# nrf9120_MLM1 register map
Vendor: Nordic Semiconductor; Series: nrf91; File version: 1
CPU: CM4 r0p1, little endian, MPU, FPU, 3 interrupt priority bits
Registers are 32-bit, read-write, reset 0x0 unless marked. A register's access mark holds for its fields unless they carry their own. Offsets are from the block's base; [hi:lo] are bit positions; 'fields as' and 'values as' point back to an identical list.

## REGULATORS — Voltage Regulators control
Base 0x40003000
0x434 DISABLEHPBOR — Enable or disable HPBOR
  [0] DISABLE
    0=Enabled (Enable HPBOR); 1=Disabled (Disable HPBOR)
0x500 SYSTEMOFF wo
  [0] SYSTEMOFF — Enable System OFF mode
    1=Enable System OFF mode
0x508 UNUSED0 — Unspecified
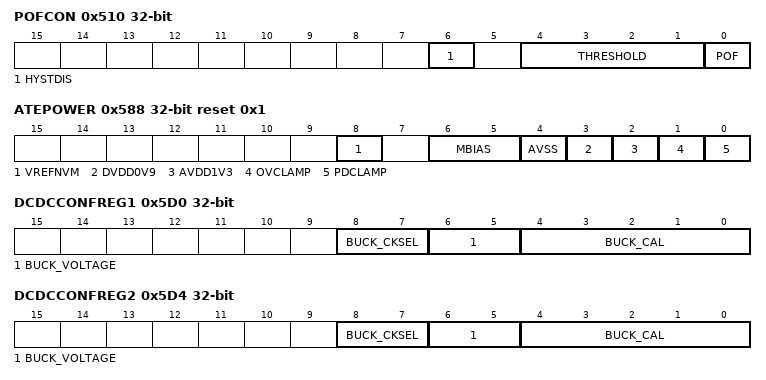
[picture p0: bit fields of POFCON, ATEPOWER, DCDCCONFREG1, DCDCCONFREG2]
0x510 POFCON — Power failure comparator configuration
  [6] HYSTDIS — Bypass power failure comparator hysteresis
    0=Normal (Hysteresis active); 1=NoHyst (Hysteresis disabled)
  [4:1] THRESHOLD — Power failure comparator threshold setting
    4=V17 (Set threshold to 1.7 V); 5=V18 (Set threshold to 1.8 V); 6=V19 (Set threshold to 1.9 V); 7=V20 (Set threshold to 2.0 V); 8=V21 (Set threshold to 2.1 V); 9=V22 (Set threshold to 2.2 V); 10=V23 (Set threshold to 2.3 V); 11=V24 (Set threshold to 2.4 V); 12=V25 (Set threshold to 2.5 V); 13=V26 (Set threshold to 2.6 V); 14=V27 (Set threshold to 2.7 V); 15=V28 (Set threshold to 2.8 V)
  [0] POF — Enable or disable power failure comparator
    0=Disabled; 1=Enabled
0x548 FORCEOFFNVM — Force off NVM supply. See also the internal section in the NVMC chapter.
  [31:0] FORCEOFFNVM
    on read: 0=DoNotForceOff (Read: Do not force off NVM supply.); 1=ForceOff (Read: Force off NVM supply.) | on write: 0=DisableForceOff (Write: Do not force off NVM supply.); 0xBADCA81E=EnableForceOff (Write: Force off NVM supply.)
0x578 DCDCEN — DC/DC enable register for REG1 (DVDD_0V9).
  [0] DCDCEN — Enable or disable DC/DC converter
    0=Disabled; 1=Enabled
0x57C DCDCEN2 — DC/DC enable register for REG2 (AVDD_1V3)
  [0] DCDCEN — Enable or disable DC/DC mode.
    0=Disabled; 1=Enabled
0x580 DCDCENMIR — Enable mirroring of DCDCEN register into DCDCEN2 register.
  [0] DCDCENMIR — Enable or disable mirroring of DCDCEN register into DCDCEN2 register.
    0=Disabled (DCDCEN and DCDCEN2 can be set independently); 1=Enabled (DCDCEN2 is a mirrored version of DCDCEN register.)
0x588 ATEPOWER reset 0x1 — Analog test bus control for power modules
  [8] VREFNVM — Connect or disconnect reference generator for flash to analog test bus
    0=Disconnected; 1=Connected (Connect 0.9 V downscaled reference voltage to ATB0)
  [6:5] MBIAS — Configure connection of master bias generator to analog test bus
    0=Disconnected; 1=VBG (Connect 0.9 V bandgap voltage to ATB0); 2=IBPSR10U (Connect 10 uA IBPSR current to ATB1); 3=Both (Connect both VBG to ATB0 and IBPSR10U to ATB1)
  [4] AVSS — Connect or disconnect AVSS to analog test bus
    0=Disconnected; 1=Connected (Connect to ATB1)
  [3] DVDD0V9 — Connect or disconnect DVDD_0V9 to analog test bus
    0=Disconnected; 1=Connected (Connect to ATB0)
  [2] AVDD1V3 — Connect or disconnect AVDD_1V3 to analog test bus
    0=Disconnected; 1=Connected (Connect to ATB0)
  [1] OVCLAMP — Enable or disable overvoltage clamp on analog test bus
    0=Disabled; 1=Enabled
  [0] PDCLAMP — Enable or disable power-down clamp on analog test bus
    0=Disabled; 1=Enabled
0x5D0 DCDCCONFREG1 — Configuration register for REG1 DCDC regulator (DVDD_0V9).
  [8:7] BUCK_CKSEL — Input clock selection.
    0=NORMAL (normal clock); 1=INVERTED (inverted clock)
  [6:5] BUCK_VOLTAGE — Output voltage selection.
    0=1V00 (1.00 V); 1=1V09 (1.09 V); 2=1V17 (1.17 V); 3=1V26 (1.26 V)
  [4:0] BUCK_CAL — Output voltage calibration. 0: Minimum output voltage level. 31: Maximum output voltage level.
0x5D4 DCDCCONFREG2 — Configuration register for REG2 DCDC regulator (AVDD_1V3).
  fields as DCDCCONFREG1
0xA08 UNUSED1 — Unspecified
0xA0C UNUSED2 — Unspecified
0xA10 FORCEMODEREG1 — A backdoor register for manual selection of REG1 regulator mode (DVDD_0V9)
  [6:0] FORCEMODE — Force Regulator Power Mode
    0=EXT (Force external (DVDD_0V9 supplied externally)); 1=ULP (Force ULP mode); 2=LDO (Force LDO mode); 3=DCDC (Force DCDC mode); 4=DCDC_REFRESH (Force DCDC REFRESH mode)
0xA20 THRESHOLDREG1 wo — Set threshold value of REG1 DCDC regulator
  [6:0] THRESHOLD — Sets the threshold value of power regulator. Note: The reset value comes from FICR (see FICR chapter for details)
0xA24 ENFORCEMODEREG1 wo — Enable forcing of power mode in REG1 voltage regulator
  [0] ENFORCEMODE — Enable forcing of power mode in voltage regulator
    0=Disabled (Regulator mode forcing OFF); 1=Enabled (Regulator forced ON in a power mode given by FORCEREGMODE1)
0xA28 IGNOREDAPCMODE wo — Ignore DAPCP power mode
  [0] IGNOREDAPCMODE — Ignore power request from debugger
    0=Do not ignore power request form debugger; 1=Ignore power request from debugger
0xA2C CURRENTMODEREG1 ro — Currently used power mode of the REG1 voltage regulator
  [6:0] CURRENTMODE — Currently used mode of the voltage regulator
    0=EXT (Externally supplied DVDD_0V9); 2=DCDC (DCDC mode); 3=DCDC_REFRESH (DCDC REFRESH mode); 4=LDO (LDO mode); 6=LDO_DCDC (swithching between LDO and DCDC (in any direction) Intermediate state when both regulators are ON); 7=LDO_DCDC_REFRESH (swithching between LDO and DCDC-REFRESH (in any direction) Intermediate state when both regulators are ON); 8=ULP (ULP mode); 10=DCDC_ULP (swithching from DCDC to ULP Intermediate state when both regulators are ON); 11=DCDC_REFRESH_ULP (swithching from DCDC-REFRESH to ULP Intermediate state when both regulators are ON); 12=ULP_LDO (swithching between ULP and LDO (in any direction) Intermediate state when both regulators are ON)
0xA30 FORCEMODEREG2 — A backdoor register for manual selection of REG2 regulator mode (DVDD_1V3)
  [6:0] FORCEMODE — Force Regulator Power Mode
    0=EXT (Force external (AVDD_1V3 supplied externally)); 1=ULP (Force ULP mode); 2=LDO (Force LDO mode); 3=DCDC (Force DCDC mode); 4=DCDC_REFRESH (Force DCDC REFRESH mode)
0xA38 THRESHOLDREG2 wo — Set threshold value of REG2 DCDC regulator
  fields as THRESHOLDREG1
0xA3C ENFORCEMODEREG2 wo — Enable forcing of power mode in REG2 voltage regulator
  [0] ENFORCEMODE — Enable forcing of power mode in voltage regulator
    0=Disabled (Regulator mode forcing OFF); 1=Enabled (Regulator forced ON in a power mode given by FORCEREGMODE2)
0xA40 DISABLEHSLIMITREG2 — Disable HSLIMIT for REG2 DCDC regulator
  [0] DISABLE — Enable or disable HSLIMIT for DCDC regulator
    0=Enabled (Enable HSLIMIT); 1=Disabled (Disable HSLIMIT)
0xA44 CURRENTMODEREG2 ro — Currently used power mode of the REG2 voltage regulator
  [6:0] CURRENTMODE — Currently used mode of the voltage regulator
    0=EXT (Externally supplied AVDD_1V3); 2=DCDC (DCDC mode); 3=DCDC_REFRESH (DCDC REFRESH mode); 4=LDO (LDO mode); 6=LDO_DCDC (swithching between LDO and DCDC (in any direction) Intermediate state when both regulators are ON); 7=LDO_DCDC_REFRESH (swithching between LDO and DCDC-REFRESH (in any direction) Intermediate state when both regulators are ON); 8=ULP (ULP mode); 10=DCDC_ULP (swithching from DCDC to ULP Intermediate state when both regulators are ON); 11=DCDC_REFRESH_ULP (swithching from DCDC-REFRESH to ULP Intermediate state when both regulators are ON); 12=ULP_LDO (swithching between ULP and LDO (in any direction) Intermediate state when both regulators are ON)
0xA48 DISABLEHSLIMITREG1 — Disable HSLIMIT for REG1 DCDC regulator
  fields as DISABLEHSLIMITREG2
0xA54 LDOCONFREG1 — Configuration register for REG1 LDO regulator (DVDD_0V9).
  [2:0] VREGTRIM — Output voltage calibration.
    3=1.163 V; 2=1.136 V; 1=1.108 V; 0=1.082 V; 7=1.054 V; 6=1.029 V; 5=1.003 V; 4=0.980 V
0xA58 LDOTESTLOADREG1 — Test load setting for REG1 LDO regulator (DVDD_0V9).
  [2:0] VREGLOAD — Output load configuration (for test purposes)
    0=Normal operation (default); 1=1mA test load; 2=50mA test load; 3=150mA test load
0xA5C LDOCONFREG2 — Configuration register for REG2 LDO regulator (AVDD_1V3).
  [2:0] VREGTRIM — Output voltage calibration.
    3=1.357 V; 2=1.324 V; 1=1.289 V; 0=1.255 V; 7=1.219 V; 6=1.185 V; 5=1.150 V; 4=0.117 V
0xA60 LDOTESTLOADREG2 — Test load setting for REG2 LDO regulator (AVDD_1V3).
  fields as LDOTESTLOADREG1
0xA64 ULPCONFREG1 — Configuration register for REG1 ULP regulator (DVDD_0V9).
  [2:0] ULPTRIM — Output voltage calibration. 0: minimum voltage 7: maximum voltage
0xA68 ULPCONFREG2 — Configuration register for REG2 ULP regulator (AVDD_1V3).
  fields as ULPCONFREG1
0xA6C VREG_HIGH_REG1 — Increase voltage to AVDD_1V3 levels for REG1 LDO regulator (DVDD_0V9)
  [0] ENABLE — Enable or disable the feature
    0=Disabled (Nominal output levels of REG1 LDO); 1=Enabled (Increased output levels of REG1 LDO)
0xA70 ULP_HIGH_REG1 — Increase voltage to AVDD_1V3 ULP levels for REG1 ULP regulator (DVDD_0V9)
  [0] ENABLE — Enable or disable the feature
    0=Disabled (Nominal output levels of REG1 ULP); 1=Enabled (Increased output levels of REG1 ULP)
0xEE8 DISABLESRAMSYSTEMOFFACK — Enable or disable System OFF ack from SRAM
  [0] DISABLE
    0=Enabled (Enable ack); 1=Disabled (Disable ack)
0xEEC DISABLENVMSYSTEMOFFACK — Enable or disable System OFF ack from NVM
  [0] DISABLE
    0=Enabled (Enable ack); 1=Disabled (Disable ack)
